AUTOSAR XML (schema 00046)
package /ComponentTypes
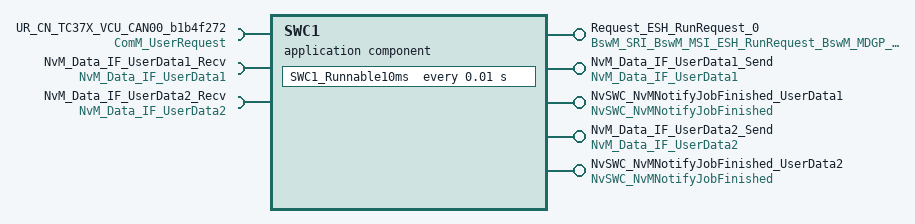
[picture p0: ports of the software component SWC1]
  application sw component type SWC1
    provide port Request_ESH_RunRequest_0: nonqueued-sender-com-spec=requestedMode, provided-interface=BswM_SRI_BswM_MSI_ESH_RunRequest_BswM_MDGP_ESH_RunRequest
    require port UR_CN_TC37X_VCU_CAN00_b1b4f272: required-com-specs=[RequestComMode, GetCurrentComMode, GetMaxComMode, GetRequestedComMode], required-interface=ComM_UserRequest
    provide port NvM_Data_IF_UserData1_Send: nv-provide-com-spec{ram-block-init-value=10 x 0, rom-block-init-value=10 x 0, variable=Element_UserData1}, provided-interface=NvM_Data_IF_UserData1
    require port NvM_Data_IF_UserData1_Recv: nv-require-com-spec{init-value=10 x 0, variable=Element_UserData1}, required-interface=NvM_Data_IF_UserData1
    provide port NvSWC_NvMNotifyJobFinished_UserData1: server-com-spec{operation=JobFinished, queue-length=1}, provided-interface=NvSWC_NvMNotifyJobFinished
    provide port NvM_Data_IF_UserData2_Send: nv-provide-com-spec=Element_UserData2, provided-interface=NvM_Data_IF_UserData2
    require port NvM_Data_IF_UserData2_Recv: nv-require-com-spec=Element_UserData2, required-interface=NvM_Data_IF_UserData2
    provide port NvSWC_NvMNotifyJobFinished_UserData2: server-com-spec{operation=JobFinished, queue-length=1}, provided-interface=NvSWC_NvMNotifyJobFinished
    behavior SWC1_InternalBehavior
      init event SWC1_InitEvent: start-on-event=SWC1_Init
      timing event TMT_SWC1_Runnable10ms: start-on-event=SWC1_Runnable10ms, period=0.01
      operation invoked event OIT_NvSWC_NvMNotifyJobFinished_UserData1_JobFinished_NvSWC_NvMNotifyJobFinished_UserData1_JobFinished: start-on-event=NvSWC_NvMNotifyJobFinished_UserData1_JobFinished, operation=NvSWC_NvMNotifyJobFinished_UserData1.JobFinished
      operation invoked event OIT_NvSWC_NvMNotifyJobFinished_UserData2_JobFinished_NvSWC_NvMNotifyJobFinished_UserData2_JobFinished: start-on-event=NvSWC_NvMNotifyJobFinished_UserData2_JobFinished, operation=NvSWC_NvMNotifyJobFinished_UserData2.JobFinished
      4 x runnable:
        SWC1_Init
          data-send-points:
            access SEND_Request_ESH_RunRequest_0_requestedMode: accessed-variable=Request_ESH_RunRequest_0.requestedMode
        SWC1_Runnable10ms
          data-receive-point-by-arguments:
            access REC_NvM_Data_IF_UserData1_Recv_Element_UserData1: accessed-variable=NvM_Data_IF_UserData1_Recv.Element_UserData1
            access REC_NvM_Data_IF_UserData2_Recv_Element_UserData2: accessed-variable=NvM_Data_IF_UserData2_Recv.Element_UserData2
          data-send-points:
            access SEND_NvM_Data_IF_UserData1_Send_Element_UserData1: accessed-variable=NvM_Data_IF_UserData1_Send.Element_UserData1
            access SEND_NvM_Data_IF_UserData2_Send_Element_UserData2: accessed-variable=NvM_Data_IF_UserData2_Send.Element_UserData2
          sync call SC_UR_CN_TC37X_VCU_CAN00_b1b4f272_RequestComMode: operation=UR_CN_TC37X_VCU_CAN00_b1b4f272.RequestComMode
        NvSWC_NvMNotifyJobFinished_UserData1_JobFinished
        NvSWC_NvMNotifyJobFinished_UserData2_JobFinished
  swc implementation SWC1_Implementation: behavior=SWC1_InternalBehavior
